AUTOSAR XML (schema 314)
package /ComponentType
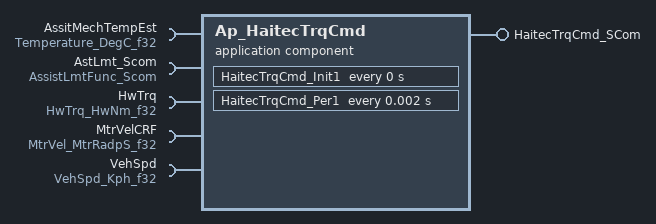
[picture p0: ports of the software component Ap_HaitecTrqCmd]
  application software component type Ap_HaitecTrqCmd
    provide port HaitecTrqCmd_SCom: provided-com-specs=[{operation=StartCtrl, queue-length=1}, {operation=StopCtrl, queue-length=1}], provided-interface=HaitecTrqCmd_SCom
    5 x require port:
      AssitMechTempEst: unqueued-receiver-com-spec{data-element=DegC_f32, init-value=D_ZERO_ULS_F32}, required-interface=Temperature_DegC_f32
      AstLmt_Scom: required-com-specs=[GetSteeringAssistDefeat, ManualTrqCmd, SetSteeringAssistDefeat], required-interface=AssistLmtFunc_Scom
      HwTrq: unqueued-receiver-com-spec{data-element=HwNm_f32, init-value=D_ZERO_ULS_F32}, required-interface=HwTrq_HwNm_f32
      MtrVelCRF: unqueued-receiver-com-spec{data-element=MtrRadpS_f32, init-value=D_ZERO_ULS_F32}, required-interface=MtrVel_MtrRadpS_f32
      VehSpd: unqueued-receiver-com-spec{data-element=Kph_f32, init-value=D_ZERO_ULS_F32}, required-interface=VehSpd_Kph_f32
  internal behavior Ap_HaitecTrqCmd_InternalBehavior: component=Ap_HaitecTrqCmd
    timing event HaitecTrqCmd_Init1_InitEvent: start-on-event=HaitecTrqCmd_Init1, period=0
    timing event TMT_HaitecTrqCmd_Per1: start-on-event=HaitecTrqCmd_Per1, period=0.002
    operation invoked event OIT_HaitecTrqCmd_SCom_StartCtrl_HaitecTrqCmd_SCom_StartCtrl: start-on-event=HaitecTrqCmd_SCom_StartCtrl, operation=HaitecTrqCmd_SCom.StartCtrl
    operation invoked event OIT_HaitecTrqCmd_SCom_StopCtrl_HaitecTrqCmd_SCom_StopCtrl: start-on-event=HaitecTrqCmd_SCom_StopCtrl, operation=HaitecTrqCmd_SCom.StopCtrl
    port-api-options:
      enable-take-address=false, indirect-api=false, port=AssitMechTempEst
      enable-take-address=false, indirect-api=false, port=AstLmt_Scom
      enable-take-address=false, indirect-api=false, port=HaitecTrqCmd_SCom
      enable-take-address=false, indirect-api=false, port=HwTrq
      enable-take-address=false, indirect-api=false, port=MtrVelCRF
      enable-take-address=false, indirect-api=false, port=VehSpd
    4 x runnable:
      HaitecTrqCmd_Init1
      HaitecTrqCmd_Per1
        4 x data read access:
          READ_AssitMechTempEst_DegC_f32: data-element=AssitMechTempEst.DegC_f32
          READ_HwTrq_HwNm_f32: data-element=HwTrq.HwNm_f32
          READ_MtrVelCRF_MtrRadpS_f32: data-element=MtrVelCRF.MtrRadpS_f32
          READ_VehSpd_Kph_f32: data-element=VehSpd.Kph_f32
        sync call SC_AstLmt_Scom_ManualTrqCmd: operation=AstLmt_Scom.ManualTrqCmd, timeout=0
      HaitecTrqCmd_SCom_StartCtrl
        data receive point REC_AssitMechTempEst_DegC_f32: data-element=AssitMechTempEst.DegC_f32
        data receive point REC_VehSpd_Kph_f32: data-element=VehSpd.Kph_f32
      HaitecTrqCmd_SCom_StopCtrl
        sync call SC_AstLmt_Scom_ManualTrqCmd: operation=AstLmt_Scom.ManualTrqCmd, timeout=0
  swc implementation Ap_HaitecTrqCmd_Implementation: behavior=Ap_HaitecTrqCmd_InternalBehavior
    code-descriptors:
      code Code: type=SRC
